# SN32F420 register map
Vendor: SONiX Technology Co., Ltd.; Series: SN32F420; File version: 1.00
CPU: CM0 r0p0, little endian, no MPU, no FPU, 2 interrupt priority bits
Registers are 32-bit, read-write, reset 0x0 unless marked. A register's access mark holds for its fields unless they carry their own. Offsets are from the block's base; [hi:lo] are bit positions; {n}, {i} and the like mark numbered series; 'fields as' and 'values as' point back to an identical list.

## SN_ADC — ADC
Base 0x40026000
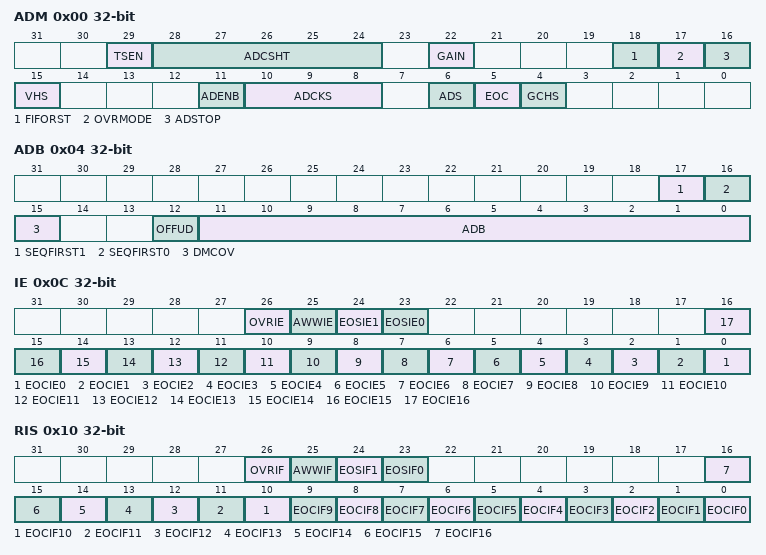
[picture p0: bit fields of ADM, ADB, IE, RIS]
0x00 ADM — Offset:0x00 ADC Management register
  [29] TSEN — Temp sensor enable bit
    0=Disable temperature sensor; 1=Enable temperature sensor
  [28:24] ADCSHT — ADC clock cycles of sampling
    {v}={v+5} cycles (Sample cycle = {v+5} cycles) (v=0..31)
  [22] GAIN — ADC gain select bit
    0=ADC gain = 1; 1=ADC gain = 2/3
  [18] FIFORST wo — ADB FIFO Reset bit
    0=No (No effect); 1=Reset ADB FIFO
  [17] OVRMODE — Overrun mode select bit
    0=Preserve (The old data is preserved when the overrun occurs); 1=Overwrite (The ADC data FIFO is overwritted with the latest data)
  [16] ADSTOP — ADC stop control bit
    0=No (No effect); 1=Stop (ADC stops converting)
  [15] VHS — ADC internal reference voltage select bit
    0=Internal reference voltage 2.4V; 1=VDD
  [11] ADENB — ADC enable
    0=Disable ADC; 1=Enable ADC
  [10:8] ADCKS — ADC clock source divider
    0=000b (ADC_PCLK/1); 1=001b (ADC_PCLK/2); 2=010b (ADC_PCLK/4); 3=011b (ADC_PCLK/8); 4=100b (ADC_PCLK/16); 5=101b (ADC_PCLK/32)
  [6] ADS — ADC start control
    0=Stop (ADC stops); 1=Start ADC conversion
  [5] EOC ro — ADC status
    0=Busy (ADC is processing); 1=End (End of processing)
  [4] GCHS — ADC global channel enable
    0=Disable AIN channel; 1=Enable AIN channel
0x04 ADB ro — Offset:0x04 ADC Data register
  [17] SEQFIRST1 — First channel ADB of Sequence 1
    0=Not first channel ADB of Sequence 1; 1=First channel ADB of Sequence 1
  [16] SEQFIRST0 — First channel ADB of Sequence 0
    0=Not first channel ADB of Sequence 0; 1=First channel ADB of Sequence 0
  [15] DMCOV — Modulation Overflow flag
    0=No overflow (The data has not modulation overflow.); 1=Overflow (The data has modulation overflow.)
  [12] OFFUD — Offset underflow flag
    0=No underflow (The data has not offset underflow.); 1=Underflow (The data has offset underflow.)
  [11:0] ADB — ADB11~ADB0 bits for 12-bit ADC
0x0C IE — Offset:0x0C ADC Interrupt Enable register
  [26] OVRIE — ADC Overrun interrupt enable
    0=Disable OVR interrupt; 1=Enable (ADC interrupt is triggered when ADB overrun happens)
  [25] AWWIE — ADC Window watchdog interrupt enable
    0=Disable AWW interrupt; 1=Enable (ADC interrupt is triggered when ADB meets AWW condition)
  [24] EOSIE1 — EOS1 interrupt enable
    0=Disable end of Sequence 1 interrupt; 1=Enable (ADC interrupt is triggered when all channels in a sequence completes ADC conversion)
  [23] EOSIE0 — EOS0 interrupt enable
    0=Disable end of Sequence 0 interrupt; 1=Enable (ADC interrupt is triggered when all channels in a sequence completes ADC conversion)
  [n] EOCIE{n} (n=0..16) — AIN{n} EOC interrupt enable
    0=Disable AIN{n} EOC interrupt; 1=Enable (ADC interrupt is triggered when AIN{n} completes ADC conversion)
0x10 RIS ro — Offset:0x10 ADC Raw Interrupt Status register
  [26] OVRIF — Overrun interrupt flag
    0=No interrupt requirement met; 1=Met interrupt requirements (ADB FIFO overrun)
  [25] AWWIF — ADC Window Watchdog interrupt flag
    0=No interrupt requirement met; 1=Met interrupt requirements (ADB matches AWW condition)
  [24] EOSIF1 — End of sequence 1 interrupt flag
    0=No interrupt (No sequence of conversion is completed); 1=Met interrupt requirements (The multiple channels selected by SQR1 register are all converted)
  [23] EOSIF0 — End of sequence 0 interrupt flag
    0=No interrupt (No sequence of conversion is completed); 1=Met interrupt requirements (The multiple channels selected by SQR0 register are all converted)
  [n] EOCIF{n} (n=0..16) — AIN{n} interrupt flag
    0=No interrupt on AIN{n}; 1=Met interrupt requirements (AIN{n} completes ADC conversion)
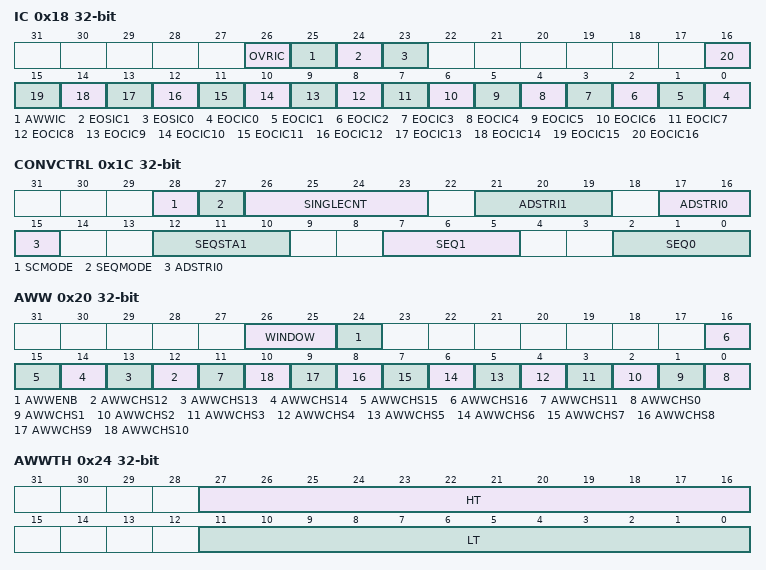
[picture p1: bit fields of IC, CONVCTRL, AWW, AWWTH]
0x18 IC wo — Offset:0x18 ADC Interrupt Clear register
  [26] OVRIC — Overrun interrupt flag clear bit
    0=No (No effect); 1=Clear OVRIF bit
  [25] AWWIC — ADC Window Watchdog interrupt flag clear bit
    0=No (No effect); 1=Clear AWWIF bit
  [24] EOSIC1 — End of sequence 1 interrupt flag clear bit
    0=No (No effect); 1=Clear EOSIF1 bit
  [23] EOSIC0 — End of sequence 0 interrupt flag clear bit
    0=No (No effect); 1=Clear EOSIF0 bit
  [n] EOCIC{n} (n=0..16) — AIN{n} interrupt flag clear bit
    0=No (No effect); 1=Clear EOCIF{n} bit
0x1C CONVCTRL — Offset:0x1C ADC Convert Control register
  [28] SCMODE — Single/Continuous mode
    0=Single mode; 1=Continuous mode
  [27] SEQMODE — The sequence mode selection
    0=The single sequence mode; 1=The dual sequences mode
  [26:23] SINGLECNT — The number of MT/UT16Bx flag triggers required to start a single sequence mode.
    0=1 trigger; {v}={v+1} triggers (v=1..15)
  [21:19] ADSTRI1 — ADC start conversion trigger source 1 selection for sequence 1.
    0=000b (ADS bit (Software mode)); 1=001b (MT16B0 TADC0IF rising edge); 2=010b (MT16B0 TADC1IF rising edge); 3=011b (UT16B0 MR0IF rising edge); 4=100b (UT16B0 MR1IF rising edge); 5=101b (UT16B1 MR0IF rising edge); 6=110b (UT16B1 MR1IF rising edge)
  [17:15] ADSTRI0 — ADC start conversion trigger source 0 selection for sequence 0.
    values as ADSTRI1
  [12:10] SEQSTA1 — The first channel of sequence 1
    {v}=SQC{v+1} (v=0..7)
  [7:5] SEQ1 — The number of conversion channels for sequence 1 in single or dual sequence mode
    0=1 channel is converted of sequence 1 in single or dual sequences; {v}={v+1} channels are converted of sequence 1 in single or dual sequences (v=1..7)
  [2:0] SEQ0 — The number of conversion channels for sequence 0 in single or dual sequence mode
    0=1 channel is converted of sequence 0 in single or dual sequences; {v}={v+1} channels are converted of sequence 0 in single or dual sequences (v=1..7)
0x20 AWW — Offset:0x20 ADC Window Watchdog register
  [26:25] WINDOW — AWW window selection bits
    0=More (ADB is more than AWW high threshold); 1=Between (ADB is between AWW high threshold and low threshold); 2=Less (ADB is less than AWW low threshold)
  [24] AWWENB — ADC Window watchdog enable bit
    0=Disable AWW; 1=Enable AWW
  [n] AWWCHS{n} (n=12..16) — AIN{n} Window watchdog select bit
    0=Disable AWW for AIN{n}; 1=Enable AWW for AIN{n}
  [11] AWWCHS11 — AIN1 Window watchdog select bit
    0=Disable AWW for AIN11; 1=Enable AWW for AIN11
  [n] AWWCHS{n} (n=0..10) — AIN{n} Window watchdog select bit
    0=Disable AWW for AIN{n}; 1=Enable AWW for AIN{n}
0x24 AWWTH — Offset:0x24 ADC Window Watchdog Threshold register
  [27:16] HT — AWW window High threshold value
  [11:0] LT — AWW window Low threshold value
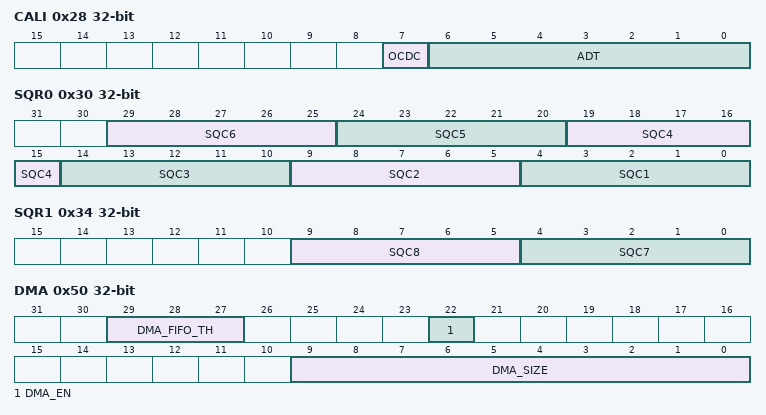
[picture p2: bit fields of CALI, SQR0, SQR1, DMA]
0x28 CALI — Offset:0x28 ADC Calibration register
  [7] OCDC — ADC offset calibration direction control bit
    0=Positive direction. Offset Data = ADCRAW - ADT[6:0].; 1=Negative direction. Offset Data = ADCRAW + ADT[6:0].
  [6:0] ADT — ADC offset calibration control bit.
0x2C DM reset 0x200 — Offset:0x2C ADC Data Modulation register
  [9:0] DMC — ADC Data Modulation control bit.
0x30 SQR0 — Offset:0x30 ADC Scan Sequence register 0
  [29:25] SQC6 — The 6th conversion channel selection for the scan mode
  [24:20] SQC5 — The 5th conversion channel selection for the scan mode
  [19:15] SQC4 — The 4th conversion channel selection for the scan mode
  [14:10] SQC3 — The 3rd conversion channel selection for the scan mode
  [9:5] SQC2 — The 2nd conversion channel selection for the scan mode
  [4:0] SQC1 — The 1st conversion channel selection for the scan mode
0x34 SQR1 — Offset:0x34 ADC Scan Sequence register 1
  [9:5] SQC8 — The 8th conversion channel selection for the scan mode
  [4:0] SQC7 — The 7th conversion channel selection for the scan mode
0x50 DMA — Offset:0x50 ADC DMA mode register
  [29:27] DMA_FIFO_TH — ADC FIFO Threshold level
    0=00000b (RX FIFO threshold level = 0); 1=00001b (RX FIFO threshold level = 1); 2=00010b (RX FIFO threshold level = 2); 3=00011b (RX FIFO threshold level = 3); 4=00100b (RX FIFO threshold level = 4); 5=00101b (RX FIFO threshold level = 5); 6=0110b (RX FIFO threshold level = 6); 7=00111b (RX FIFO threshold level = 7); 8=01000b (RX FIFO threshold level = 8); 9=01001b (RX FIFO threshold level = 9); 10=01010b (RX FIFO threshold level = 10); 11=01011b (RX FIFO threshold level = 11); 12=01100b (RX FIFO threshold level = 12); 13=01101b (RX FIFO threshold level = 13); 14=01110b (RX FIFO threshold level = 14); 15=01111b (RX FIFO threshold level = 15); 16=10000b (RX FIFO threshold level = 16 (FIFO Full))
  [22] DMA_EN — ADC DMA mode enable
    0=Disable ADC DMA mode; 1=Enable ADC DMA mode
  [9:0] DMA_SIZE — ADC DMA transfer size
